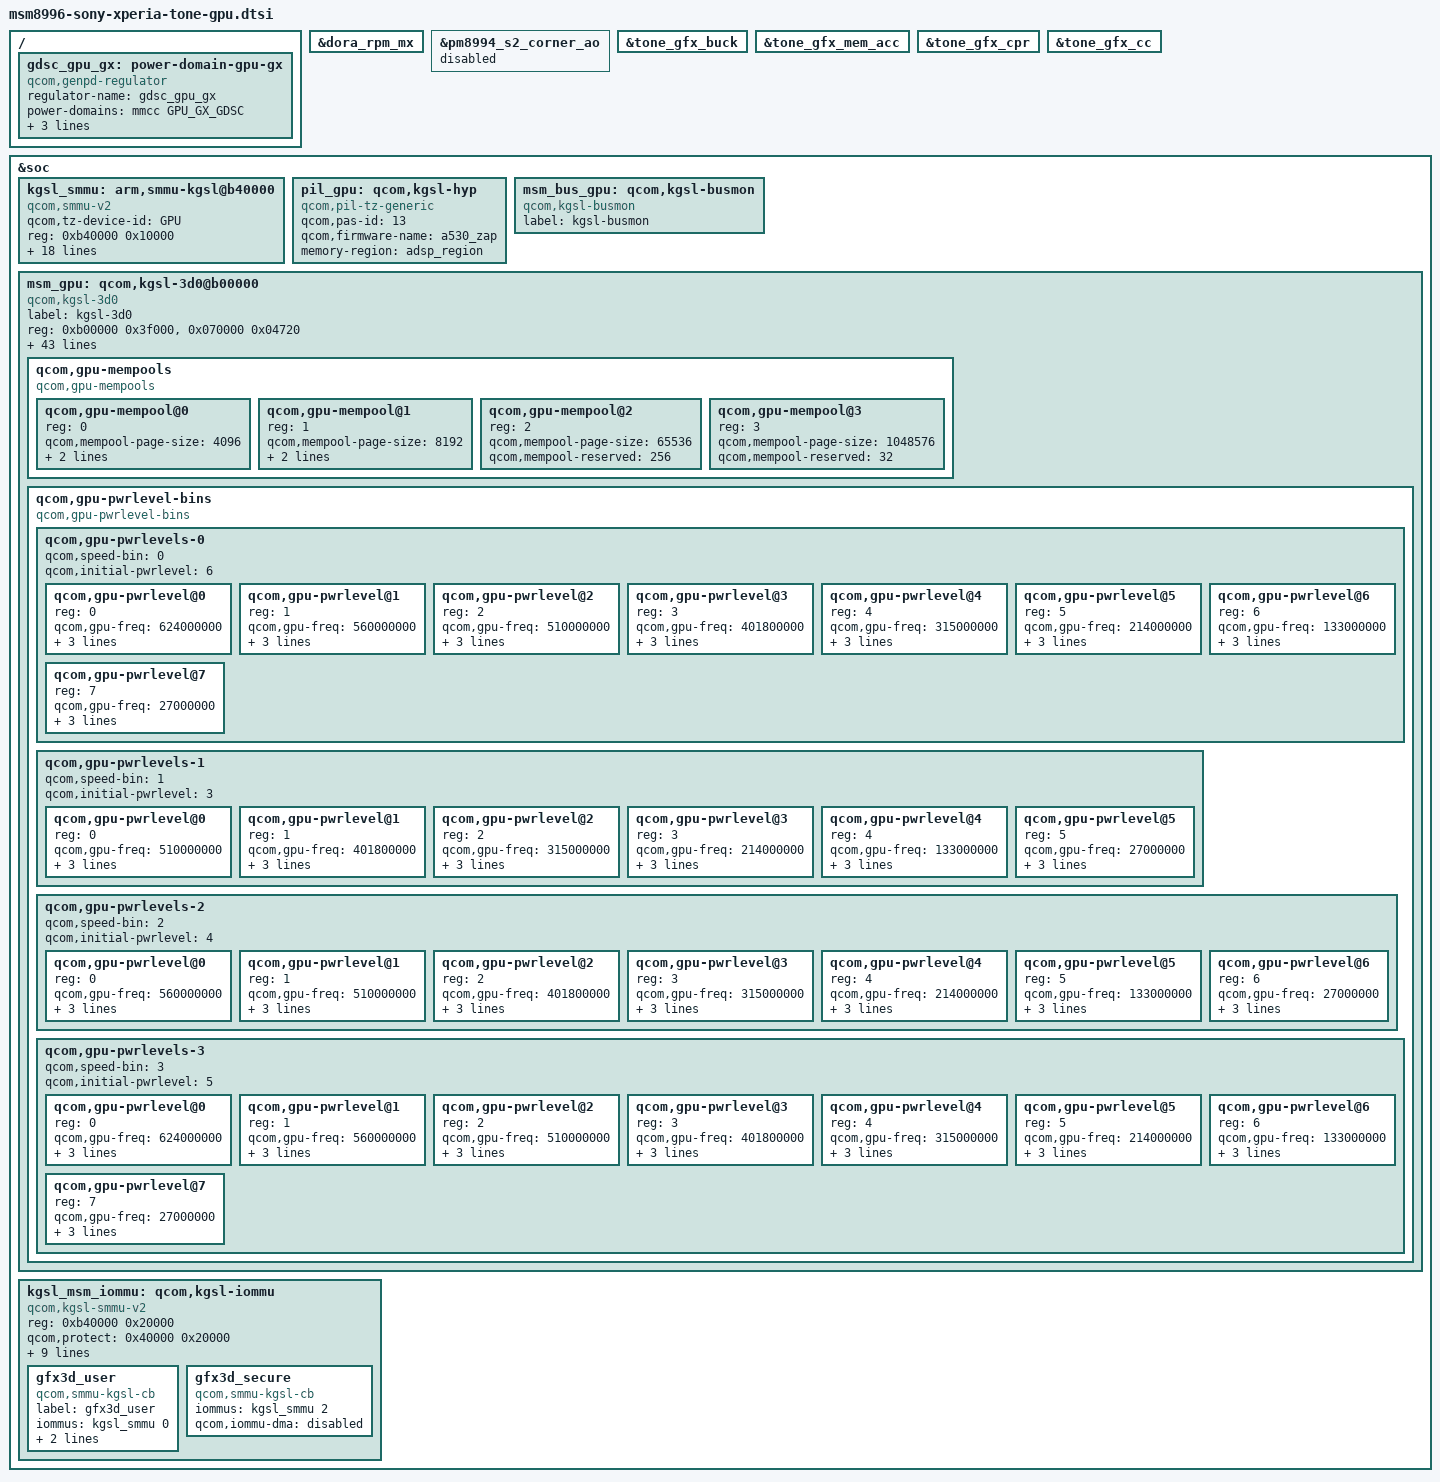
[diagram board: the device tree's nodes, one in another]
// SPDX-License-Identifier: GPL-2.0-only
/*
 * Sony Xperia X Performance (dora) MSM8996 v3.1 Adreno 530 GPU, SMMU-v2,
 * zap shader PIL, and GX/CX/CPR3/MX power sequencing for Linux 4.19.
 */

#include <dt-bindings/clock/qcom,gcc-msm8996.h>
#include <dt-bindings/clock/qcom,mmcc-msm8996.h>
#include <dt-bindings/interrupt-controller/arm-gic.h>

&dora_rpm_mx {
	status = "okay";
};

&pm8994_s2_corner_ao {
	status = "disabled";
};

&tone_gfx_buck {
	status = "okay";
};

&tone_gfx_mem_acc {
	status = "okay";
};

&tone_gfx_cpr {
	status = "okay";
};

&tone_gfx_cc {
	status = "okay";
};

/ {
	gdsc_gpu_gx: power-domain-gpu-gx {
		compatible = "qcom,genpd-regulator";
		regulator-name = "gdsc_gpu_gx";
		power-domains = <&mmcc GPU_GX_GDSC>;
		parent-supply = <&tone_gfx_vreg>;
		clocks = <&tone_gfx_cc GFX3D_CLK_SRC>;
		clock-names = "core_root_clk";
		qcom,force-enable-root-clk;
	};
};

&soc {
	kgsl_smmu: arm,smmu-kgsl@b40000 {
		status = "okay";
		compatible = "qcom,smmu-v2";
		qcom,tz-device-id = "GPU";
		reg = <0xb40000 0x10000>;
		#iommu-cells = <1>;
		qcom,register-save;
		qcom,skip-init;
		qcom,dynamic;
		#global-interrupts = <1>;
		interrupts = <GIC_SPI 334 IRQ_TYPE_LEVEL_HIGH>,
			     <GIC_SPI 329 IRQ_TYPE_LEVEL_HIGH>,
			     <GIC_SPI 330 IRQ_TYPE_LEVEL_HIGH>;
		vdd-supply = <&gdsc_gpu>;
		qcom,regulator-names = "vdd";
		clocks = <&mmcc MMSS_MMAGIC_AHB_CLK>,
			 <&mmcc MMSS_MMAGIC_CFG_AHB_CLK>,
			 <&tone_gfx_cc GPU_AHB_CLK>,
			 <&gcc GCC_MMSS_BIMC_GFX_CLK>,
			 <&gcc GCC_BIMC_GFX_CLK>;
		clock-names = "mmagic_ahb_clk", "mmagic_cfg_ahb_clk",
			      "gpu_ahb_clk", "gcc_mmss_bimc_gfx_clk",
			      "gcc_bimc_gfx_clk";
		#clock-cells = <1>;
		attach-impl-defs = <0x6000 0x70>,
				   <0x6060 0x1055>,
				   <0x6a00 0x6>,
				   <0x6b00 0x3ff>,
				   <0x6b18 0x3>,
				   <0x6b24 0x204>,
				   <0x6b28 0x11000>,
				   <0x6b30 0x800>,
				   <0x678c 0x8>,
				   <0x6794 0x28>;
	};

	pil_gpu: qcom,kgsl-hyp {
		compatible = "qcom,pil-tz-generic";
		qcom,pas-id = <13>;
		qcom,firmware-name = "a530_zap";
		memory-region = <&adsp_region>;
	};

	msm_bus_gpu: qcom,kgsl-busmon {
		label = "kgsl-busmon";
		compatible = "qcom,kgsl-busmon";
	};

	msm_gpu: qcom,kgsl-3d0@b00000 {
		label = "kgsl-3d0";
		compatible = "qcom,kgsl-3d0", "qcom,kgsl-3d";
		status = "okay";
		reg = <0xb00000 0x3f000>,
		      <0x070000 0x04720>;
		reg-names = "kgsl_3d0_reg_memory", "qfprom_memory";
		interrupts = <GIC_SPI 300 IRQ_TYPE_LEVEL_HIGH>;
		interrupt-names = "kgsl_3d0_irq";
		qcom,id = <0>;

		qcom,chipid = <0x05030002>;
		qcom,bus-width = <32>;
		qcom,gpu-quirk-two-pass-use-wfi;
		qcom,gpu-quirk-critical-packets;
		qcom,gpu-quirk-fault-detect-mask;

		qcom,base-leakage-coefficient = <34>;
		qcom,lm-limit = <6000>;
		qcom,initial-pwrlevel = <2>;
		qcom,idle-timeout = <80>;
		qcom,deep-nap-timeout = <20>;
		qcom,strtstp-sleepwake;
		qcom,highest-bank-bit = <15>;
		qcom,snapshot-size = <1048576>;

		qcom,gpmu-tsens = <0x00060007>;
		qcom,lm-max-power = <5448>;
		qcom,gpmu-firmware = "a530v3_gpmu.fw2";
		qcom,gpmu-version = <1 0>;
		qcom,zap-shader = "a530_zap";

		nvmem-cells = <&sony_cpu_speedbin>;
		nvmem-cell-names = "speed_bin";

		clocks = <&tone_gfx_cc GPU_GX_GFX3D_CLK>,
			 <&tone_gfx_cc GPU_AHB_CLK>,
			 <&tone_gfx_cc GPU_GX_RBBMTIMER_CLK>,
			 <&gcc GCC_BIMC_GFX_CLK>,
			 <&gcc GCC_MMSS_BIMC_GFX_CLK>,
			 <&mmcc MMSS_MMAGIC_AHB_CLK>;
		clock-names = "core_clk", "iface_clk", "rbbmtimer_clk",
			      "mem_clk", "mem_iface_clk", "alt_mem_iface_clk";

		qcom,bus-control;
		qcom,msm-bus-provider = <&ad_hoc_bus>;
		qcom,msm-bus,name = "grp3d";
		qcom,msm-bus,num-cases = <13>;
		qcom,msm-bus,num-paths = <1>;
		qcom,msm-bus,vectors-KBps =
			<26 512 0 0>,
			<26 512 0 800000>,
			<26 512 0 1200000>,
			<26 512 0 1600000>,
			<26 512 0 2400000>,
			<26 512 0 3296000>,
			<26 512 0 4376000>,
			<26 512 0 5448000>,
			<26 512 0 6144000>,
			<26 512 0 8136000>,
			<26 512 0 10368000>,
			<26 512 0 12440000>,
			<26 512 0 14432000>;

		regulator-names = "vddcx", "vdd";
		vddcx-supply = <&gdsc_gpu>;
		vdd-supply = <&gdsc_gpu_gx>;

		qcom,gpu-mempools {
			#address-cells = <1>;
			#size-cells = <0>;
			compatible = "qcom,gpu-mempools";

			qcom,gpu-mempool@0 {
				reg = <0>;
				qcom,mempool-page-size = <4096>;
				qcom,mempool-reserved = <2048>;
				qcom,mempool-allocate;
			};

			qcom,gpu-mempool@1 {
				reg = <1>;
				qcom,mempool-page-size = <8192>;
				qcom,mempool-reserved = <1024>;
				qcom,mempool-allocate;
			};

			qcom,gpu-mempool@2 {
				reg = <2>;
				qcom,mempool-page-size = <65536>;
				qcom,mempool-reserved = <256>;
			};

			qcom,gpu-mempool@3 {
				reg = <3>;
				qcom,mempool-page-size = <1048576>;
				qcom,mempool-reserved = <32>;
			};
		};

		qcom,gpu-pwrlevel-bins {
			#address-cells = <1>;
			#size-cells = <0>;
			compatible = "qcom,gpu-pwrlevel-bins";

			qcom,gpu-pwrlevels-0 {
				#address-cells = <1>;
				#size-cells = <0>;
				qcom,speed-bin = <0>;
				qcom,initial-pwrlevel = <6>;

				qcom,gpu-pwrlevel@0 {
					reg = <0>;
					qcom,gpu-freq = <624000000>;
					qcom,bus-freq = <12>;
					qcom,bus-min = <11>;
					qcom,bus-max = <12>;
				};

				qcom,gpu-pwrlevel@1 {
					reg = <1>;
					qcom,gpu-freq = <560000000>;
					qcom,bus-freq = <11>;
					qcom,bus-min = <9>;
					qcom,bus-max = <12>;
				};

				qcom,gpu-pwrlevel@2 {
					reg = <2>;
					qcom,gpu-freq = <510000000>;
					qcom,bus-freq = <9>;
					qcom,bus-min = <8>;
					qcom,bus-max = <11>;
				};

				qcom,gpu-pwrlevel@3 {
					reg = <3>;
					qcom,gpu-freq = <401800000>;
					qcom,bus-freq = <8>;
					qcom,bus-min = <7>;
					qcom,bus-max = <9>;
				};

				qcom,gpu-pwrlevel@4 {
					reg = <4>;
					qcom,gpu-freq = <315000000>;
					qcom,bus-freq = <6>;
					qcom,bus-min = <5>;
					qcom,bus-max = <7>;
				};

				qcom,gpu-pwrlevel@5 {
					reg = <5>;
					qcom,gpu-freq = <214000000>;
					qcom,bus-freq = <4>;
					qcom,bus-min = <3>;
					qcom,bus-max = <5>;
				};

				qcom,gpu-pwrlevel@6 {
					reg = <6>;
					qcom,gpu-freq = <133000000>;
					qcom,bus-freq = <3>;
					qcom,bus-min = <2>;
					qcom,bus-max = <4>;
				};

				qcom,gpu-pwrlevel@7 {
					reg = <7>;
					qcom,gpu-freq = <27000000>;
					qcom,bus-freq = <0>;
					qcom,bus-min = <0>;
					qcom,bus-max = <0>;
				};
			};

			qcom,gpu-pwrlevels-1 {
				#address-cells = <1>;
				#size-cells = <0>;
				qcom,speed-bin = <1>;
				qcom,initial-pwrlevel = <3>;

				qcom,gpu-pwrlevel@0 {
					reg = <0>;
					qcom,gpu-freq = <510000000>;
					qcom,bus-freq = <9>;
					qcom,bus-min = <8>;
					qcom,bus-max = <10>;
				};

				qcom,gpu-pwrlevel@1 {
					reg = <1>;
					qcom,gpu-freq = <401800000>;
					qcom,bus-freq = <8>;
					qcom,bus-min = <7>;
					qcom,bus-max = <9>;
				};

				qcom,gpu-pwrlevel@2 {
					reg = <2>;
					qcom,gpu-freq = <315000000>;
					qcom,bus-freq = <6>;
					qcom,bus-min = <5>;
					qcom,bus-max = <7>;
				};

				qcom,gpu-pwrlevel@3 {
					reg = <3>;
					qcom,gpu-freq = <214000000>;
					qcom,bus-freq = <4>;
					qcom,bus-min = <3>;
					qcom,bus-max = <5>;
				};

				qcom,gpu-pwrlevel@4 {
					reg = <4>;
					qcom,gpu-freq = <133000000>;
					qcom,bus-freq = <3>;
					qcom,bus-min = <2>;
					qcom,bus-max = <4>;
				};

				qcom,gpu-pwrlevel@5 {
					reg = <5>;
					qcom,gpu-freq = <27000000>;
					qcom,bus-freq = <0>;
					qcom,bus-min = <0>;
					qcom,bus-max = <0>;
				};
			};

			qcom,gpu-pwrlevels-2 {
				#address-cells = <1>;
				#size-cells = <0>;
				qcom,speed-bin = <2>;
				qcom,initial-pwrlevel = <4>;

				qcom,gpu-pwrlevel@0 {
					reg = <0>;
					qcom,gpu-freq = <560000000>;
					qcom,bus-freq = <11>;
					qcom,bus-min = <11>;
					qcom,bus-max = <11>;
				};

				qcom,gpu-pwrlevel@1 {
					reg = <1>;
					qcom,gpu-freq = <510000000>;
					qcom,bus-freq = <9>;
					qcom,bus-min = <8>;
					qcom,bus-max = <10>;
				};

				qcom,gpu-pwrlevel@2 {
					reg = <2>;
					qcom,gpu-freq = <401800000>;
					qcom,bus-freq = <8>;
					qcom,bus-min = <7>;
					qcom,bus-max = <9>;
				};

				qcom,gpu-pwrlevel@3 {
					reg = <3>;
					qcom,gpu-freq = <315000000>;
					qcom,bus-freq = <6>;
					qcom,bus-min = <5>;
					qcom,bus-max = <7>;
				};

				qcom,gpu-pwrlevel@4 {
					reg = <4>;
					qcom,gpu-freq = <214000000>;
					qcom,bus-freq = <4>;
					qcom,bus-min = <3>;
					qcom,bus-max = <5>;
				};

				qcom,gpu-pwrlevel@5 {
					reg = <5>;
					qcom,gpu-freq = <133000000>;
					qcom,bus-freq = <3>;
					qcom,bus-min = <2>;
					qcom,bus-max = <4>;
				};

				qcom,gpu-pwrlevel@6 {
					reg = <6>;
					qcom,gpu-freq = <27000000>;
					qcom,bus-freq = <0>;
					qcom,bus-min = <0>;
					qcom,bus-max = <0>;
				};
			};

			qcom,gpu-pwrlevels-3 {
				#address-cells = <1>;
				#size-cells = <0>;
				qcom,speed-bin = <3>;
				qcom,initial-pwrlevel = <5>;

				qcom,gpu-pwrlevel@0 {
					reg = <0>;
					qcom,gpu-freq = <624000000>;
					qcom,bus-freq = <12>;
					qcom,bus-min = <11>;
					qcom,bus-max = <12>;
				};

				qcom,gpu-pwrlevel@1 {
					reg = <1>;
					qcom,gpu-freq = <560000000>;
					qcom,bus-freq = <11>;
					qcom,bus-min = <9>;
					qcom,bus-max = <12>;
				};

				qcom,gpu-pwrlevel@2 {
					reg = <2>;
					qcom,gpu-freq = <510000000>;
					qcom,bus-freq = <9>;
					qcom,bus-min = <8>;
					qcom,bus-max = <11>;
				};

				qcom,gpu-pwrlevel@3 {
					reg = <3>;
					qcom,gpu-freq = <401800000>;
					qcom,bus-freq = <8>;
					qcom,bus-min = <7>;
					qcom,bus-max = <9>;
				};

				qcom,gpu-pwrlevel@4 {
					reg = <4>;
					qcom,gpu-freq = <315000000>;
					qcom,bus-freq = <6>;
					qcom,bus-min = <5>;
					qcom,bus-max = <7>;
				};

				qcom,gpu-pwrlevel@5 {
					reg = <5>;
					qcom,gpu-freq = <214000000>;
					qcom,bus-freq = <4>;
					qcom,bus-min = <3>;
					qcom,bus-max = <5>;
				};

				qcom,gpu-pwrlevel@6 {
					reg = <6>;
					qcom,gpu-freq = <133000000>;
					qcom,bus-freq = <3>;
					qcom,bus-min = <2>;
					qcom,bus-max = <4>;
				};

				qcom,gpu-pwrlevel@7 {
					reg = <7>;
					qcom,gpu-freq = <27000000>;
					qcom,bus-freq = <0>;
					qcom,bus-min = <0>;
					qcom,bus-max = <0>;
				};
			};
		};
	};

	kgsl_msm_iommu: qcom,kgsl-iommu {
		compatible = "qcom,kgsl-smmu-v2";
		reg = <0xb40000 0x20000>;
		qcom,protect = <0x40000 0x20000>;
		qcom,micro-mmu-control = <0x6000>;

		clocks = <&mmcc MMSS_MMAGIC_AHB_CLK>,
			 <&mmcc MMSS_MMAGIC_CFG_AHB_CLK>,
			 <&tone_gfx_cc GPU_AHB_CLK>,
			 <&gcc GCC_MMSS_BIMC_GFX_CLK>,
			 <&gcc GCC_BIMC_GFX_CLK>;
		clock-names = "mmagic_ahb_clk", "mmagic_cfg_ahb_clk",
			      "gpu_ahb_clk", "gcc_mmss_bimc_gfx_clk",
			      "gcc_bimc_gfx_clk";

		qcom,secure_align_mask = <0xfff>;
		qcom,retention;
		qcom,hyp_secure_alloc;

		gfx3d_user: gfx3d_user {
			compatible = "qcom,smmu-kgsl-cb";
			label = "gfx3d_user";
			iommus = <&kgsl_smmu 0>;
			qcom,iommu-dma = "disabled";
			qcom,gpu-offset = <0x48000>;
		};

		gfx3d_secure: gfx3d_secure {
			compatible = "qcom,smmu-kgsl-cb";
			iommus = <&kgsl_smmu 2>;
			qcom,iommu-dma = "disabled";
		};
	};
};
